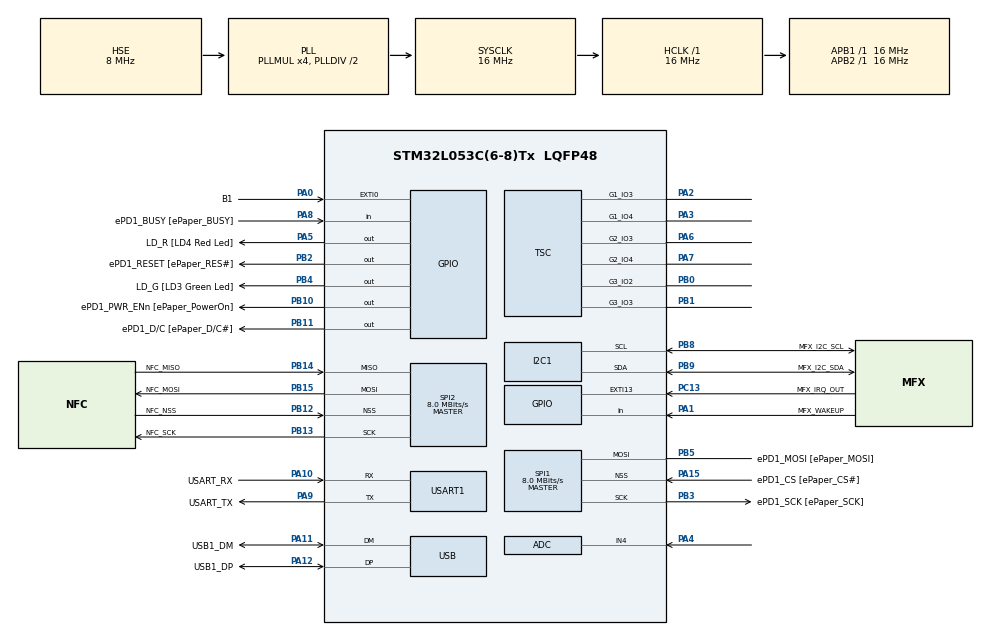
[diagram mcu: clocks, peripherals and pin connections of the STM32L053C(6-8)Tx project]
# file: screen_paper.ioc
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ADC.ContinuousConvMode=DISABLE
ADC.DMAContinuousRequests=ENABLE
ADC.ExternalTrigConv=ADC_EXTERNALTRIGCONV_T6_TRGO
ADC.SamplingTime=ADC_SAMPLETIME_19CYCLES_5
Dma.ADC.0.Direction=DMA_PERIPH_TO_MEMORY
Dma.ADC.0.Instance=DMA1_Channel1
Dma.ADC.0.MemDataAlignment=DMA_MDATAALIGN_HALFWORD
Dma.ADC.0.MemInc=DMA_MINC_DISABLE
Dma.ADC.0.Mode=DMA_CIRCULAR
Dma.ADC.0.PeriphDataAlignment=DMA_PDATAALIGN_HALFWORD
Dma.ADC.0.PeriphInc=DMA_PINC_DISABLE
Dma.ADC.0.Priority=DMA_PRIORITY_LOW
Dma.Request0=ADC
I2C1.Timing=0x00303D5B
Mcu.Family=STM32L0
Mcu.Name=STM32L053C(6-8)Tx
Mcu.Package=LQFP48
NVIC.ADC1_COMP_IRQn=true\:0\:0\:false\:false\:true\:true\:true
NVIC.DMA1_Channel1_IRQn=true\:0\:0\:false\:false\:true\:false\:true
NVIC.EXTI0_1_IRQn=true\:0\:0\:false\:false\:true\:true\:true
NVIC.TIM21_IRQn=true\:0\:0\:false\:false\:true\:true\:true
PA0.GPIO_Label=B1
PA0.GPIO_ModeDefaultEXTI=GPIO_MODE_IT_RISING
PA0.GPIO_PuPd=GPIO_PULLDOWN
PA0.Signal=GPXTI0
PA1.GPIO_Label=MFX_WAKEUP
PA1.Signal=GPIO_Input
PA10.GPIO_Label=USART_RX
PA10.Mode=Asynchronous
PA10.Signal=USART1_RX
PA11.GPIO_Label=USB1_DM
PA11.Mode=Device
PA11.Signal=USB_DM
PA12.GPIO_Label=USB1_DP
PA12.Mode=Device
PA12.Signal=USB_DP
PA13.GPIO_Label=SWDIO
PA13.Mode=Serial_Wire
PA13.Signal=SYS_SWDIO
PA14.GPIO_Label=SWCLK
PA14.Mode=Serial_Wire
PA14.Signal=SYS_SWCLK
PA15.GPIO_Label=ePD1_CS [ePaper_CS\#]
PA15.GPIO_Mode=GPIO_MODE_AF_PP
PA15.GPIO_PuPd=GPIO_NOPULL
PA15.GPIO_Speed=GPIO_SPEED_FREQ_LOW
PA15.Mode=NSS_Signal_Hard_Input
PA15.Signal=SPI1_NSS
PA2.Mode=G1_IO3-Channel
PA2.Signal=TSC_G1_IO3
PA3.Mode=G1_IO4-Sampling
PA3.Signal=TSC_G1_IO4
PA4.Mode=IN4
PA4.Signal=ADC_IN4
PA5.GPIO_Label=LD_R [LD4 Red Led]
PA5.GPIO_ModeDefaultOutputPP=GPIO_MODE_OUTPUT_PP
PA5.GPIO_PuPd=GPIO_NOPULL
PA5.GPIO_Speed=GPIO_SPEED_FREQ_LOW
PA5.Signal=GPIO_Output
PA6.Mode=G2_IO3-Channel
PA6.Signal=TSC_G2_IO3
PA7.Mode=G2_IO4-Sampling
PA7.Signal=TSC_G2_IO4
PA8.GPIO_Label=ePD1_BUSY [ePaper_BUSY]
PA8.GPIO_Mode=GPIO_MODE_INPUT
PA8.GPIO_PuPd=GPIO_NOPULL
PA8.Signal=GPIO_Input
PA9.GPIO_Label=USART_TX
PA9.Mode=Asynchronous
PA9.Signal=USART1_TX
PB0.Mode=G3_IO2-Channel
PB0.Signal=TSC_G3_IO2
PB1.Mode=G3_IO3-Sampling
PB1.Signal=TSC_G3_IO3
PB10.GPIO_Label=ePD1_PWR_ENn [ePaper_PowerOn]
PB10.GPIO_ModeDefaultOutputPP=GPIO_MODE_OUTPUT_PP
PB10.GPIO_PuPd=GPIO_NOPULL
PB10.GPIO_Speed=GPIO_SPEED_FREQ_LOW
PB10.Signal=GPIO_Output
PB11.GPIO_Label=ePD1_D/C [ePaper_D/C\#]
PB11.GPIO_ModeDefaultOutputPP=GPIO_MODE_OUTPUT_PP
PB11.GPIO_PuPd=GPIO_NOPULL
PB11.GPIO_Speed=GPIO_SPEED_FREQ_LOW
PB11.Signal=GPIO_Output
PB12.GPIO_Label=NFC_NSS
PB12.Mode=NSS_Signal_Hard_Input
PB12.Signal=SPI2_NSS
PB13.GPIO_Label=NFC_SCK
PB13.Mode=Full_Duplex_Master
PB13.Signal=SPI2_SCK
PB14.GPIO_Label=NFC_MISO
PB14.Mode=Full_Duplex_Master
PB14.Signal=SPI2_MISO
PB15.GPIO_Label=NFC_MOSI
PB15.Mode=Full_Duplex_Master
PB15.Signal=SPI2_MOSI
PB2.GPIO_Label=ePD1_RESET [ePaper_RES\#]
PB2.GPIO_ModeDefaultOutputPP=GPIO_MODE_OUTPUT_PP
PB2.GPIO_PuPd=GPIO_NOPULL
PB2.GPIO_Speed=GPIO_SPEED_FREQ_LOW
PB2.Signal=GPIO_Output
PB3.GPIO_Label=ePD1_SCK [ePaper_SCK]
PB3.GPIO_Mode=GPIO_MODE_AF_PP
PB3.GPIO_PuPd=GPIO_NOPULL
PB3.GPIO_Speed=GPIO_SPEED_FREQ_LOW
PB3.Mode=Simplex_Bidirectional_Master
PB3.Signal=SPI1_SCK
PB4.GPIO_Label=LD_G [LD3 Green Led]
PB4.GPIO_ModeDefaultOutputPP=GPIO_MODE_OUTPUT_PP
PB4.GPIO_PuPd=GPIO_NOPULL
PB4.GPIO_Speed=GPIO_SPEED_FREQ_LOW
PB4.Signal=GPIO_Output
PB5.GPIO_Label=ePD1_MOSI [ePaper_MOSI]
PB5.GPIO_Mode=GPIO_MODE_AF_PP
PB5.GPIO_PuPd=GPIO_NOPULL
PB5.GPIO_Speed=GPIO_SPEED_FREQ_LOW
PB5.Mode=Simplex_Bidirectional_Master
PB5.Signal=SPI1_MOSI
PB8.GPIO_Label=MFX_I2C_SCL
PB8.Mode=I2C
PB8.Signal=I2C1_SCL
PB9.GPIO_Label=MFX_I2C_SDA
PB9.Mode=I2C
PB9.Signal=I2C1_SDA
PC13.GPIO_Label=MFX_IRQ_OUT
PC13.Signal=GPXTI13
PC14-OSC32_IN.GPIO_Label=PC14-OSC32_IN
PC14-OSC32_IN.Signal=RCC_OSC32_IN
PC15-OSC32_OUT.GPIO_Label=PC15-OSC32_OUT
PC15-OSC32_OUT.Signal=RCC_OSC32_OUT
PH0-OSC_IN.GPIO_Label=MCO
PH0-OSC_IN.Mode=HSE-External-Clock-Source
PH0-OSC_IN.Signal=RCC_OSC_IN
ProjectManager.HeapSize=0x200
ProjectManager.StackSize=0x400
ProjectManager.TargetToolchain=STM32CubeIDE
RCC.AHBFreq_Value=16000000
RCC.APB1Freq_Value=16000000
RCC.APB1TimFreq_Value=16000000
RCC.APB2Freq_Value=16000000
RCC.APB2TimFreq_Value=16000000
RCC.HCLKFreq_Value=16000000
RCC.HSE_VALUE=8000000
RCC.HSI16_VALUE=16000000
RCC.HSI48MClockSelection=RCC_USBCLKSOURCE_HSI48
RCC.HSI48_VALUE=48000000
RCC.HSI_VALUE=16000000
RCC.LSE_VALUE=32768
RCC.MSI_VALUE=2097000
RCC.PLLMUL=RCC_PLLMUL_4
RCC.PLLSourceVirtual=RCC_PLLSOURCE_HSE
RCC.RTCClockSelectionVirtual=RCC_RTCCLKSOURCE_LSE
RCC.SYSCLKFreq_VALUE=16000000
RCC.SYSCLKSource=RCC_SYSCLKSOURCE_PLLCLK
RCC.VCOOutputFreq_Value=32000000
SPI1.CalculateBaudRate=8.0 MBits/s
SPI1.CalculateBaudRate-Simplex_Bidirectional_Master=16.0 MBits/s
SPI1.Direction=SPI_DIRECTION_1LINE
SPI1.Direction-Simplex_Bidirectional_Master=SPI_DIRECTION_1LINE
SPI1.Mode=SPI_MODE_MASTER
SPI1.Mode-Simplex_Bidirectional_Master=SPI_MODE_MASTER
SPI1.NSS-Simplex_Bidirectional_Master=SPI_NSS_HARD_OUTPUT
SPI1.TIMode-Simplex_Bidirectional_Master=SPI_TIMODE_DISABLE
SPI1.VirtualNSS=VM_NSSHARD
SPI1.VirtualType=VM_MASTER
SPI2.CalculateBaudRate=8.0 MBits/s
SPI2.Direction=SPI_DIRECTION_2LINES
SPI2.Mode=SPI_MODE_MASTER
SPI2.VirtualNSS=VM_NSSHARD
SPI2.VirtualType=VM_MASTER
TIM21.Period=4000
TIM21.Prescaler=16000
TIM6.Period=70
TIM6.Prescaler=16000
TIM6.TIM_MasterOutputTrigger=TIM_TRGO_UPDATE
TSC.ChannelIOs-G1_IO3=TSC_GROUP1_IO3
TSC.ChannelIOs-G2_IO3=TSC_GROUP2_IO3
TSC.ChannelIOs-G3_IO2=TSC_GROUP3_IO2
TSC.SamplingIOs-G1_IO4=TSC_GROUP1_IO4
TSC.SamplingIOs-G2_IO4=TSC_GROUP2_IO4
TSC.SamplingIOs-G3_IO3=TSC_GROUP3_IO3
USART1.VirtualMode-Asynchronous=VM_ASYNC
VP_TIM21_VS_ClockSourceINT.Mode=Internal
VP_TIM6_VS_ClockSourceINT.Mode=Enable_Timer
board=STM32L0538-DISCO

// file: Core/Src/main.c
/* USER CODE BEGIN Header */
/**
  ******************************************************************************
  * @file           : main.c
  * @brief          : Main program body
  ******************************************************************************
  * @attention
  *
  * <h2><center>&copy; Copyright (c) 2020 STMicroelectronics.
  * All rights reserved.</center></h2>
  *
  * This software component is licensed by ST under BSD 3-Clause license,
  * the "License"; You may not use this file except in compliance with the
  * License. You may obtain a copy of the License at:
  *                        opensource.org/licenses/BSD-3-Clause
  *
  ******************************************************************************
  */
/* USER CODE END Header */
#include "main.h"
#include "adc.h"
#include "dma.h"
#include "i2c.h"
#include "spi.h"
#include "tim.h"
#include "tsc.h"
#include "usart.h"
#include "usb.h"
#include "gpio.h"

/* USER CODE BEGIN Includes */
#include "paper_screen.h"
#include "keyboard.h"
//#include "gde021a1.h"
/* USER CODE END Includes */

/* USER CODE BEGIN PV */
uint16_t adc = 0;
/* USER CODE END PV */

void SystemClock_Config(void);

/* USER CODE BEGIN 0 */

void HAL_ADC_ConvCpltCallback(ADC_HandleTypeDef* hadc_var)
{
	if(hadc_var->Instance == ADC1){
		add_key_value(adc);
	}
}

/* USER CODE END 0 */

int main(void)
{

  /* MCU Configuration--------------------------------------------------------*/

  /* Reset of all peripherals, Initializes the Flash interface and the Systick. */
  HAL_Init();

  /* Configure the system clock */
  SystemClock_Config();

  /* Initialize all configured peripherals */
  MX_GPIO_Init();
  MX_DMA_Init();
  MX_I2C1_Init();
  MX_SPI1_Init();
  MX_SPI2_Init();
  MX_TSC_Init();
  MX_USART1_UART_Init();
  MX_USB_PCD_Init();
  MX_ADC_Init();
  MX_TIM6_Init();
  MX_TIM21_Init();
  /* USER CODE BEGIN 2 */
  BSP_EPD_Init();
  gde021a1_Init();
  // for debug // BEGIN
	draw_main_screen();
	HAL_ADCEx_Calibration_Start(&hadc, 0);

//temp for adc keyboard // keyboard_init ?) in future in keyboard_core.c
	keyboard_init();
	HAL_ADC_Start_DMA(&hadc, (uint32_t*)&adc, 1);
	HAL_TIM_Base_Start(&htim6);

  /* USER CODE END 2 */

  /* Infinite loop */
  while (1)
  {

  }
}

void SystemClock_Config(void)
{
  RCC_OscInitTypeDef RCC_OscInitStruct = {0};
  RCC_ClkInitTypeDef RCC_ClkInitStruct = {0};
  RCC_PeriphCLKInitTypeDef PeriphClkInit = {0};

  /** Configure the main internal regulator output voltage
  */
  __HAL_PWR_VOLTAGESCALING_CONFIG(PWR_REGULATOR_VOLTAGE_SCALE1);
  /** Initializes the RCC Oscillators according to the specified parameters
  * in the RCC_OscInitTypeDef structure.
  */
  RCC_OscInitStruct.OscillatorType = RCC_OSCILLATORTYPE_HSE|RCC_OSCILLATORTYPE_HSI48;
  RCC_OscInitStruct.HSEState = RCC_HSE_BYPASS;
  RCC_OscInitStruct.HSI48State = RCC_HSI48_ON;
  RCC_OscInitStruct.PLL.PLLState = RCC_PLL_ON;
  RCC_OscInitStruct.PLL.PLLSource = RCC_PLLSOURCE_HSE;
  RCC_OscInitStruct.PLL.PLLMUL = RCC_PLLMUL_4;
  RCC_OscInitStruct.PLL.PLLDIV = RCC_PLLDIV_2;
  if (HAL_RCC_OscConfig(&RCC_OscInitStruct) != HAL_OK)
  {
    Error_Handler();
  }
  /** Initializes the CPU, AHB and APB buses clocks
  */
  RCC_ClkInitStruct.ClockType = RCC_CLOCKTYPE_HCLK|RCC_CLOCKTYPE_SYSCLK
                              |RCC_CLOCKTYPE_PCLK1|RCC_CLOCKTYPE_PCLK2;
  RCC_ClkInitStruct.SYSCLKSource = RCC_SYSCLKSOURCE_PLLCLK;
  RCC_ClkInitStruct.AHBCLKDivider = RCC_SYSCLK_DIV1;
  RCC_ClkInitStruct.APB1CLKDivider = RCC_HCLK_DIV1;
  RCC_ClkInitStruct.APB2CLKDivider = RCC_HCLK_DIV1;

  if (HAL_RCC_ClockConfig(&RCC_ClkInitStruct, FLASH_LATENCY_0) != HAL_OK)
  {
    Error_Handler();
  }
  PeriphClkInit.PeriphClockSelection = RCC_PERIPHCLK_USART1|RCC_PERIPHCLK_I2C1
                              |RCC_PERIPHCLK_USB;
  PeriphClkInit.Usart1ClockSelection = RCC_USART1CLKSOURCE_PCLK2;
  PeriphClkInit.I2c1ClockSelection = RCC_I2C1CLKSOURCE_PCLK1;
  PeriphClkInit.UsbClockSelection = RCC_USBCLKSOURCE_HSI48;
  if (HAL_RCCEx_PeriphCLKConfig(&PeriphClkInit) != HAL_OK)
  {
    Error_Handler();
  }
}

void Error_Handler(void)
{
}

/************************ (C) COPYRIGHT STMicroelectronics *****END OF FILE****/
